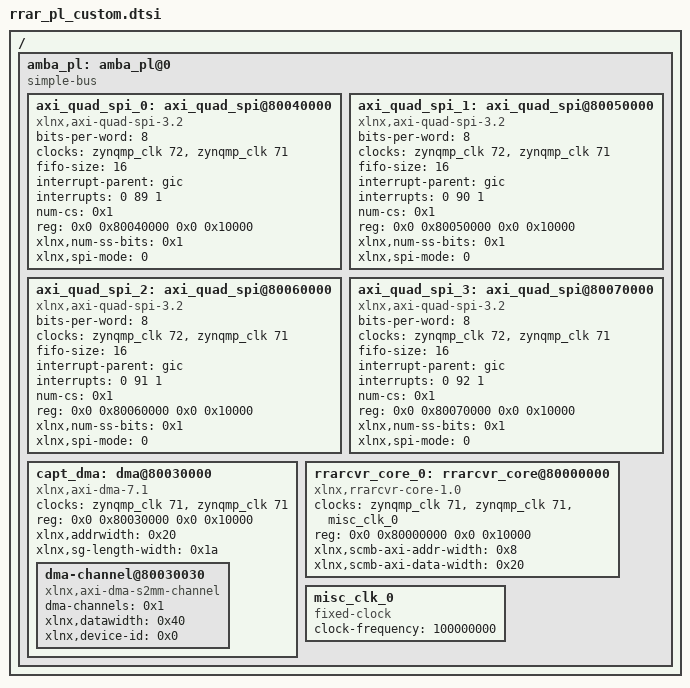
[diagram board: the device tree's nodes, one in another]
/*
 * CAUTION: This file is automatically generated by Xilinx.
 * Version:  
 * Today is: Thu Nov  7 07:56:04 2024
 */


/ {
	amba_pl: amba_pl@0 {
		#address-cells = <2>;
		#size-cells = <2>;
		compatible = "simple-bus";
		ranges ;
		axi_quad_spi_0: axi_quad_spi@80040000 {
			bits-per-word = <8>;
			clock-names = "ext_spi_clk", "s_axi_aclk";
			clocks = <&zynqmp_clk 72>, <&zynqmp_clk 71>;
			compatible = "xlnx,axi-quad-spi-3.2", "xlnx,xps-spi-2.00.a";
			fifo-size = <16>;
			interrupt-names = "ip2intc_irpt";
			interrupt-parent = <&gic>;
			interrupts = <0 89 1>;
			num-cs = <0x1>;
			reg = <0x0 0x80040000 0x0 0x10000>;
			xlnx,num-ss-bits = <0x1>;
			xlnx,spi-mode = <0>;
		};
		axi_quad_spi_1: axi_quad_spi@80050000 {
			bits-per-word = <8>;
			clock-names = "ext_spi_clk", "s_axi_aclk";
			clocks = <&zynqmp_clk 72>, <&zynqmp_clk 71>;
			compatible = "xlnx,axi-quad-spi-3.2", "xlnx,xps-spi-2.00.a";
			fifo-size = <16>;
			interrupt-names = "ip2intc_irpt";
			interrupt-parent = <&gic>;
			interrupts = <0 90 1>;
			num-cs = <0x1>;
			reg = <0x0 0x80050000 0x0 0x10000>;
			xlnx,num-ss-bits = <0x1>;
			xlnx,spi-mode = <0>;
		};
		axi_quad_spi_2: axi_quad_spi@80060000 {
			bits-per-word = <8>;
			clock-names = "ext_spi_clk", "s_axi_aclk";
			clocks = <&zynqmp_clk 72>, <&zynqmp_clk 71>;
			compatible = "xlnx,axi-quad-spi-3.2", "xlnx,xps-spi-2.00.a";
			fifo-size = <16>;
			interrupt-names = "ip2intc_irpt";
			interrupt-parent = <&gic>;
			interrupts = <0 91 1>;
			num-cs = <0x1>;
			reg = <0x0 0x80060000 0x0 0x10000>;
			xlnx,num-ss-bits = <0x1>;
			xlnx,spi-mode = <0>;
		};
		axi_quad_spi_3: axi_quad_spi@80070000 {
			bits-per-word = <8>;
			clock-names = "ext_spi_clk", "s_axi_aclk";
			clocks = <&zynqmp_clk 72>, <&zynqmp_clk 71>;
			compatible = "xlnx,axi-quad-spi-3.2", "xlnx,xps-spi-2.00.a";
			fifo-size = <16>;
			interrupt-names = "ip2intc_irpt";
			interrupt-parent = <&gic>;
			interrupts = <0 92 1>;
			num-cs = <0x1>;
			reg = <0x0 0x80070000 0x0 0x10000>;
			xlnx,num-ss-bits = <0x1>;
			xlnx,spi-mode = <0>;
		};
		capt_dma: dma@80030000 {
			#dma-cells = <1>;
			clock-names = "s_axi_lite_aclk", "m_axi_s2mm_aclk";
			clocks = <&zynqmp_clk 71>, <&zynqmp_clk 71>;
			compatible = "xlnx,axi-dma-7.1", "xlnx,axi-dma-1.00.a";
			reg = <0x0 0x80030000 0x0 0x10000>;
			xlnx,addrwidth = <0x20>;
			xlnx,sg-length-width = <0x1a>;
			dma-channel@80030030 {
				compatible = "xlnx,axi-dma-s2mm-channel";
				dma-channels = <0x1>;
				xlnx,datawidth = <0x40>;
				xlnx,device-id = <0x0>;
			};
		};
		rrarcvr_core_0: rrarcvr_core@80000000 {
			clock-names = "sCMB_axi_aclk", "aclk", "ddr_ui_clk";
			clocks = <&zynqmp_clk 71>, <&zynqmp_clk 71>, <&misc_clk_0>;
			compatible = "xlnx,rrarcvr-core-1.0";
			reg = <0x0 0x80000000 0x0 0x10000>;
			xlnx,scmb-axi-addr-width = <0x8>;
			xlnx,scmb-axi-data-width = <0x20>;
		};
		misc_clk_0: misc_clk_0 {
			#clock-cells = <0>;
			clock-frequency = <100000000>;
			compatible = "fixed-clock";
		};
	};
};
